# CY8C3866PVI_021 register map
File version: 0.1
Registers are 8-bit, read-write, no defined reset value unless marked. A register's access mark holds for its fields unless they carry their own. Offsets are from the block's base; [hi:lo] are bit positions; {n}, {i} and the like mark numbered series.

## USBUART_1 — USBFS
Base 0x00004394
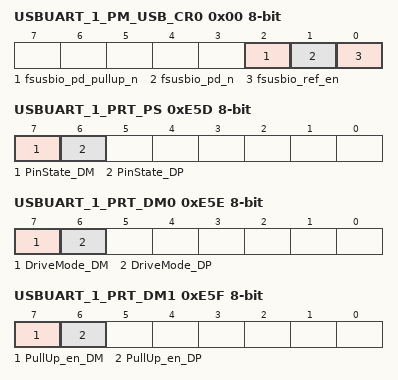
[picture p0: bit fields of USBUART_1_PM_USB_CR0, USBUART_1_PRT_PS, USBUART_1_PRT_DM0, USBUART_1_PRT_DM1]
0x00 USBUART_1_PM_USB_CR0 — USB Power Mode Control Register 0
  [2] fsusbio_pd_pullup_n, [1] fsusbio_pd_n, [0] fsusbio_ref_en
0x11 USBUART_1_PM_ACT_CFG — Active Power Mode Configuration Register
0x21 USBUART_1_PM_STBY_CFG — Standby Power Mode Configuration Register
0xE5D USBUART_1_PRT_PS — Port Pin State Register
  [7] PinState_DM ro, [6] PinState_DP ro
0xE5E USBUART_1_PRT_DM0 — Port Drive Mode Register
  [7] DriveMode_DM, [6] DriveMode_DP
0xE5F USBUART_1_PRT_DM1 — Port Drive Mode Register
  [7] PullUp_en_DM, [6] PullUp_en_DP
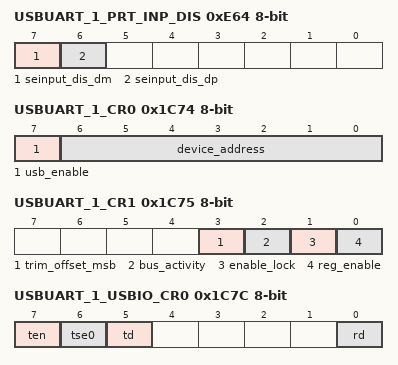
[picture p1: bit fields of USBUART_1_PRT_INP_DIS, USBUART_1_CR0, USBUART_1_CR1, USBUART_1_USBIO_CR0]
0xE64 USBUART_1_PRT_INP_DIS — Input buffer disable override
  [7] seinput_dis_dm, [6] seinput_dis_dp
0x1C6C USBUART_1_EP0_DR0 — bmRequestType
0x1C6D USBUART_1_EP0_DR1 — bRequest
0x1C6E USBUART_1_EP0_DR2 — wValueLo
0x1C6F USBUART_1_EP0_DR3 — wValueHi
0x1C70 USBUART_1_EP0_DR4 — wIndexLo
0x1C71 USBUART_1_EP0_DR5 — wIndexHi
0x1C72 USBUART_1_EP0_DR6 — lengthLo
0x1C73 USBUART_1_EP0_DR7 — lengthHi
0x1C74 USBUART_1_CR0 — USB Control Register 0
  [7] usb_enable, [6:0] device_address ro
0x1C75 USBUART_1_CR1 — USB Control Register 1
  [3] trim_offset_msb, [2] bus_activity, [1] enable_lock, [0] reg_enable
{0x1C6A+0x10*i} USBUART_1_SIE_EP{i}_CR0 (i=1..8) — The Endpoint{i} Control Register
0x1C7C USBUART_1_USBIO_CR0 — USBIO Control Register 0
  [7] ten, [6] tse0, [5] td, [0] rd ro
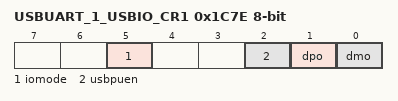
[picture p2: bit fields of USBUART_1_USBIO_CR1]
0x1C7E USBUART_1_USBIO_CR1 — USBIO Control Register 1
  [5] iomode, [2] usbpuen, [1] dpo ro, [0] dmo ro
0x1CF8 USBUART_1_BUF_SIZE — Dedicated Endpoint Buffer Size Register
0x1CFA USBUART_1_EP_ACTIVE — Endpoint Active Indication Register
0x1CFB USBUART_1_EP_TYPE — Endpoint Type (IN/OUT) Indication
0x1D09 USBUART_1_USB_CLK_EN — USB Block Clock Enable Register

## I2C
Base 0x000049C8
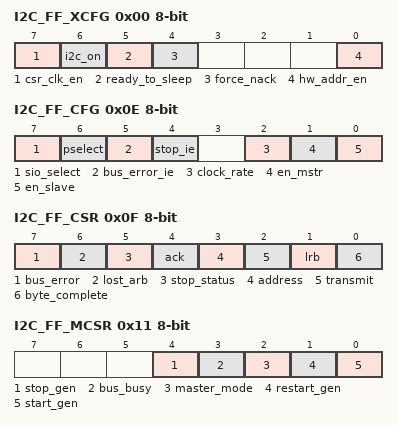
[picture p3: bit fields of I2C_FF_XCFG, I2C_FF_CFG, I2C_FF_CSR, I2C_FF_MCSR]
0x00 I2C_FF_XCFG — Extended Configuration Register: I2C_XCFG
  [7] csr_clk_en, [6] i2c_on, [5] ready_to_sleep ro, [4] force_nack, [0] hw_addr_en
0x02 I2C_FF_ADDR — Slave Adddress Register: I2C_ADR
  [6:0] slave_address — This register holds the slave's 7-bit address.
0x0E I2C_FF_CFG — Configuration Register: I2C_CFG
  [7] sio_select, [6] pselect, [5] bus_error_ie, [4] stop_ie, [2] clock_rate, [1] en_mstr, [0] en_slave
0x0F I2C_FF_CSR — Control and Status Register: I2C_CSR
  [7] bus_error, [6] lost_arb, [5] stop_status, [4] ack, [3] address, [2] transmit, [1] lrb, [0] byte_complete
0x10 I2C_FF_DATA — Data Register: I2C_D
  [7:0] data — This register provides read/write access to the Shift register.
0x11 I2C_FF_MCSR — Master Control and Status Register: I2C_MCSR
  [4] stop_gen, [3] bus_busy ro, [2] master_mode ro, [1] restart_gen, [0] start_gen
0x13 I2C_FF__CLK_DIV1 — Divider of BUS_CLK low part: I2C_CLK_DIV1
  [7:0] Div
0x14 I2C_FF__CLK_DIV2 — Divider high part: I2C_CLK_DIV1
  [1:0] Div

## PWM_Elv
Base 0x000043A3
0x00 PWM_Elv_GLOBAL_ENABLE — PM.ACT.CFG
  [3:0] en_timer — Enable timer/counters.
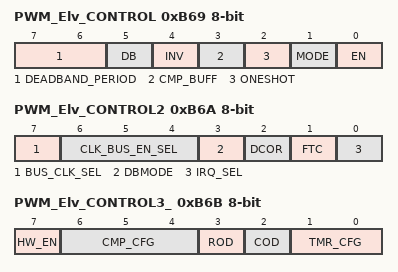
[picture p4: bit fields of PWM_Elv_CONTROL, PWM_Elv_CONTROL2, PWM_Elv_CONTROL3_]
0xB69 PWM_Elv_CONTROL — TMRx.CFG0
  [7:6] DEADBAND_PERIOD
  [5] DB — Deadband mode--Deadband phases phi1 and phi2 are outputted on CMP and TC output pins respectively.
    0=Timer (CMP and TC are output.); 1=Deadband (PHI1 (instead of CMP) and PHI2 (instead of TC) are output.)
  [4] INV — Invert sense of TIMEREN signal
  [3] CMP_BUFF — Buffer compare register. Compare register updates only on timer terminal count.
  [2] ONESHOT — Timer stops upon reaching stop condition defined by TMR_CFG bits. Can be restarted by asserting TIMER RESET or disabling and re-enabling block.
  [1] MODE ro — Mode. (0 = Timer; 1 = Comparator)
    0=Timer mode. CNT/CMP register holds timer count value.; 1=Comparator mode. CNT/CMP register holds comparator threshold value.
  [0] EN — Enables timer/comparator.
0xB6A PWM_Elv_CONTROL2 — TMRx.CFG1
  [7] BUS_CLK_SEL — Bus Clock selection.
  [6:4] CLK_BUS_EN_SEL — Digital Global Clock selection.
  [3] DBMODE — Deadband mode (asynchronous/synchronous). CMP output pin is also affected when not in deadband mode (CFG0.DEADBAND).
  [2] DCOR — Disable Clear on Read (DCOR) of Status Register SR0.
  [1] FTC — First Terminal Count (FTC). Setting this bit forces a single pulse on the TC pin when first enabled.
    0=Disable_FTC (Disable the single cycle pulse, which signifies the timer is starting.); 1=Enable_FTC (Enable the single cycle pulse, which signifies the timer is starting.)
  [0] IRQ_SEL — Irq selection. (0 = raw interrupts; 1 = status register interrupts)
0xB6B PWM_Elv_CONTROL3_ — TMRx.CFG2
  [7] HW_EN — When set Timer Enable controls counting.
  [6:4] CMP_CFG — Comparator configurations
    0=Equal (Compare Equal); 1=Less_than (Compare Less Than); 2=Less_than_or_equal (Compare Less Than or Equal .); 3=Greater (Compare Greater Than .); 4=Greater_than_or_equal (Compare Greater Than or Equal)
  [3] ROD — Reset On Disable (ROD). Resets internal state of output logic
  [2] COD — Clear On Disable (COD). Clears or gates outputs to zero.
  [1:0] TMR_CFG — Timer configuration (MODE = 0): 000 = Continuous; 001 = Pulsewidth; 010 = Period; 011 = Stop on IRQ
    0=Continuous (Timer runs while EN bit of CFG0 register is set to '1'.); 1=Pulsewidth (Timer runs from positive to negative edge of TIMEREN.); 2=Period (Timer runs from positive to positive edge of TIMEREN.); 3=Irq (Timer runs until IRQ.)
0xB6D PWM_Elv_PERIOD 16-bit — TMRx.PER0 - Assigned Period
0xB6F PWM_Elv_COMPARE 16-bit — TMRx.CNT_CMP0 - Assigned Compare Value

## PWM_Thr
Base 0x000043A3
0x00 PWM_Thr_GLOBAL_ENABLE — PM.ACT.CFG
  [3:0] en_timer — Enable timer/counters.
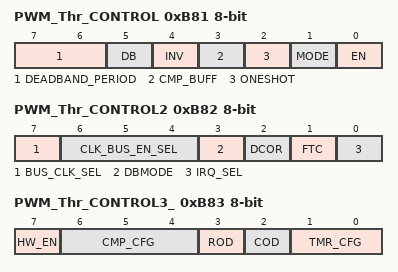
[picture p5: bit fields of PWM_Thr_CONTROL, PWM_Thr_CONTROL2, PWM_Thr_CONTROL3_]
0xB81 PWM_Thr_CONTROL — TMRx.CFG0
  [7:6] DEADBAND_PERIOD
  [5] DB — Deadband mode--Deadband phases phi1 and phi2 are outputted on CMP and TC output pins respectively.
    0=Timer (CMP and TC are output.); 1=Deadband (PHI1 (instead of CMP) and PHI2 (instead of TC) are output.)
  [4] INV — Invert sense of TIMEREN signal
  [3] CMP_BUFF — Buffer compare register. Compare register updates only on timer terminal count.
  [2] ONESHOT — Timer stops upon reaching stop condition defined by TMR_CFG bits. Can be restarted by asserting TIMER RESET or disabling and re-enabling block.
  [1] MODE ro — Mode. (0 = Timer; 1 = Comparator)
    0=Timer mode. CNT/CMP register holds timer count value.; 1=Comparator mode. CNT/CMP register holds comparator threshold value.
  [0] EN — Enables timer/comparator.
0xB82 PWM_Thr_CONTROL2 — TMRx.CFG1
  [7] BUS_CLK_SEL — Bus Clock selection.
  [6:4] CLK_BUS_EN_SEL — Digital Global Clock selection.
  [3] DBMODE — Deadband mode (asynchronous/synchronous). CMP output pin is also affected when not in deadband mode (CFG0.DEADBAND).
  [2] DCOR — Disable Clear on Read (DCOR) of Status Register SR0.
  [1] FTC — First Terminal Count (FTC). Setting this bit forces a single pulse on the TC pin when first enabled.
    0=Disable_FTC (Disable the single cycle pulse, which signifies the timer is starting.); 1=Enable_FTC (Enable the single cycle pulse, which signifies the timer is starting.)
  [0] IRQ_SEL — Irq selection. (0 = raw interrupts; 1 = status register interrupts)
0xB83 PWM_Thr_CONTROL3_ — TMRx.CFG2
  [7] HW_EN — When set Timer Enable controls counting.
  [6:4] CMP_CFG — Comparator configurations
    0=Equal (Compare Equal); 1=Less_than (Compare Less Than); 2=Less_than_or_equal (Compare Less Than or Equal .); 3=Greater (Compare Greater Than .); 4=Greater_than_or_equal (Compare Greater Than or Equal)
  [3] ROD — Reset On Disable (ROD). Resets internal state of output logic
  [2] COD — Clear On Disable (COD). Clears or gates outputs to zero.
  [1:0] TMR_CFG — Timer configuration (MODE = 0): 000 = Continuous; 001 = Pulsewidth; 010 = Period; 011 = Stop on IRQ
    0=Continuous (Timer runs while EN bit of CFG0 register is set to '1'.); 1=Pulsewidth (Timer runs from positive to negative edge of TIMEREN.); 2=Period (Timer runs from positive to positive edge of TIMEREN.); 3=Irq (Timer runs until IRQ.)
0xB85 PWM_Thr_PERIOD 16-bit — TMRx.PER0 - Assigned Period
0xB87 PWM_Thr_COMPARE 16-bit — TMRx.CNT_CMP0 - Assigned Compare Value
